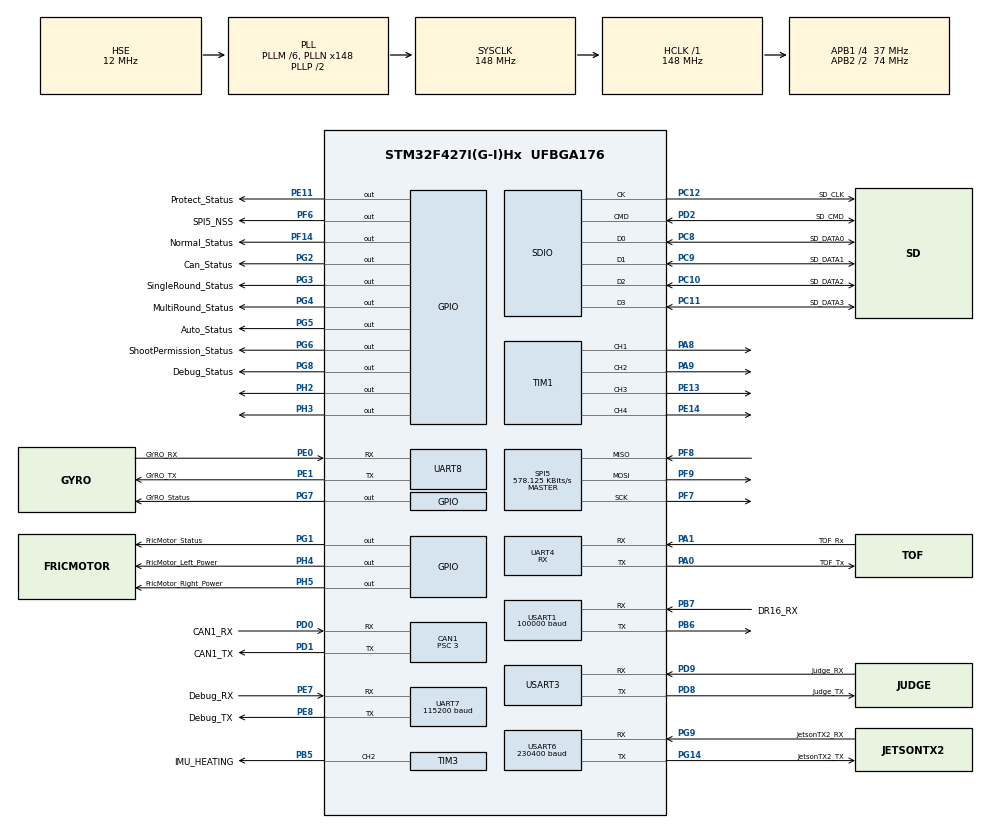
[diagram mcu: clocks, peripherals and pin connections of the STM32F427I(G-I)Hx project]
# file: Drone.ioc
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CAN1.ABOM=ENABLE
CAN1.AWUM=ENABLE
CAN1.BS1=CAN_BS1_9TQ
CAN1.BS2=CAN_BS2_4TQ
CAN1.CalculateTimeQuantum=81.08108108108108
CAN1.NART=DISABLE
CAN1.Prescaler=3
CAN1.TTCM=DISABLE
Dma.Request0=USART1_RX
Dma.Request1=USART3_RX
Dma.Request2=UART8_RX
Dma.Request3=USART6_RX
Dma.Request4=USART3_TX
Dma.Request5=USART6_TX
Dma.Request6=UART7_RX
Dma.Request7=SDIO_RX
Dma.Request8=SDIO_TX
Dma.Request9=UART4_RX
Dma.SDIO_RX.7.Direction=DMA_PERIPH_TO_MEMORY
Dma.SDIO_RX.7.FIFOMode=DMA_FIFOMODE_ENABLE
Dma.SDIO_RX.7.FIFOThreshold=DMA_FIFO_THRESHOLD_FULL
Dma.SDIO_RX.7.Instance=DMA2_Stream6
Dma.SDIO_RX.7.MemBurst=DMA_MBURST_INC4
Dma.SDIO_RX.7.MemDataAlignment=DMA_MDATAALIGN_WORD
Dma.SDIO_RX.7.MemInc=DMA_MINC_ENABLE
Dma.SDIO_RX.7.Mode=DMA_PFCTRL
Dma.SDIO_RX.7.PeriphBurst=DMA_PBURST_INC4
Dma.SDIO_RX.7.PeriphDataAlignment=DMA_PDATAALIGN_WORD
Dma.SDIO_RX.7.PeriphInc=DMA_PINC_DISABLE
Dma.SDIO_RX.7.Priority=DMA_PRIORITY_LOW
Dma.SDIO_TX.8.Direction=DMA_MEMORY_TO_PERIPH
Dma.SDIO_TX.8.FIFOMode=DMA_FIFOMODE_ENABLE
Dma.SDIO_TX.8.FIFOThreshold=DMA_FIFO_THRESHOLD_FULL
Dma.SDIO_TX.8.Instance=DMA2_Stream3
Dma.SDIO_TX.8.MemBurst=DMA_MBURST_INC4
Dma.SDIO_TX.8.MemDataAlignment=DMA_MDATAALIGN_WORD
Dma.SDIO_TX.8.MemInc=DMA_MINC_ENABLE
Dma.SDIO_TX.8.Mode=DMA_PFCTRL
Dma.SDIO_TX.8.PeriphBurst=DMA_PBURST_INC4
Dma.SDIO_TX.8.PeriphDataAlignment=DMA_PDATAALIGN_WORD
Dma.SDIO_TX.8.PeriphInc=DMA_PINC_DISABLE
Dma.SDIO_TX.8.Priority=DMA_PRIORITY_LOW
Dma.UART4_RX.9.Direction=DMA_PERIPH_TO_MEMORY
Dma.UART4_RX.9.FIFOMode=DMA_FIFOMODE_DISABLE
Dma.UART4_RX.9.Instance=DMA1_Stream2
Dma.UART4_RX.9.MemDataAlignment=DMA_MDATAALIGN_BYTE
Dma.UART4_RX.9.MemInc=DMA_MINC_ENABLE
Dma.UART4_RX.9.Mode=DMA_CIRCULAR
Dma.UART4_RX.9.PeriphDataAlignment=DMA_PDATAALIGN_BYTE
Dma.UART4_RX.9.PeriphInc=DMA_PINC_DISABLE
Dma.UART4_RX.9.Priority=DMA_PRIORITY_LOW
Dma.UART7_RX.6.Direction=DMA_PERIPH_TO_MEMORY
Dma.UART7_RX.6.FIFOMode=DMA_FIFOMODE_DISABLE
Dma.UART7_RX.6.Instance=DMA1_Stream3
Dma.UART7_RX.6.MemDataAlignment=DMA_MDATAALIGN_BYTE
Dma.UART7_RX.6.MemInc=DMA_MINC_ENABLE
Dma.UART7_RX.6.Mode=DMA_NORMAL
Dma.UART7_RX.6.PeriphDataAlignment=DMA_PDATAALIGN_BYTE
Dma.UART7_RX.6.PeriphInc=DMA_PINC_DISABLE
Dma.UART7_RX.6.Priority=DMA_PRIORITY_MEDIUM
Dma.UART8_RX.2.Direction=DMA_PERIPH_TO_MEMORY
Dma.UART8_RX.2.FIFOMode=DMA_FIFOMODE_DISABLE
Dma.UART8_RX.2.Instance=DMA1_Stream6
Dma.UART8_RX.2.MemDataAlignment=DMA_MDATAALIGN_BYTE
Dma.UART8_RX.2.MemInc=DMA_MINC_ENABLE
Dma.UART8_RX.2.Mode=DMA_NORMAL
Dma.UART8_RX.2.PeriphDataAlignment=DMA_PDATAALIGN_BYTE
Dma.UART8_RX.2.PeriphInc=DMA_PINC_DISABLE
Dma.UART8_RX.2.Priority=DMA_PRIORITY_VERY_HIGH
Dma.USART1_RX.0.Direction=DMA_PERIPH_TO_MEMORY
Dma.USART1_RX.0.FIFOMode=DMA_FIFOMODE_DISABLE
Dma.USART1_RX.0.Instance=DMA2_Stream2
Dma.USART1_RX.0.MemDataAlignment=DMA_MDATAALIGN_BYTE
Dma.USART1_RX.0.MemInc=DMA_MINC_ENABLE
Dma.USART1_RX.0.Mode=DMA_CIRCULAR
Dma.USART1_RX.0.PeriphDataAlignment=DMA_PDATAALIGN_BYTE
Dma.USART1_RX.0.PeriphInc=DMA_PINC_DISABLE
Dma.USART1_RX.0.Priority=DMA_PRIORITY_HIGH
Dma.USART3_RX.1.Direction=DMA_PERIPH_TO_MEMORY
Dma.USART3_RX.1.FIFOMode=DMA_FIFOMODE_DISABLE
Dma.USART3_RX.1.Instance=DMA1_Stream1
Dma.USART3_RX.1.MemDataAlignment=DMA_MDATAALIGN_BYTE
Dma.USART3_RX.1.MemInc=DMA_MINC_ENABLE
Dma.USART3_RX.1.Mode=DMA_NORMAL
Dma.USART3_RX.1.PeriphDataAlignment=DMA_PDATAALIGN_BYTE
Dma.USART3_RX.1.PeriphInc=DMA_PINC_DISABLE
Dma.USART3_RX.1.Priority=DMA_PRIORITY_MEDIUM
Dma.USART3_TX.4.Direction=DMA_MEMORY_TO_PERIPH
Dma.USART3_TX.4.FIFOMode=DMA_FIFOMODE_DISABLE
Dma.USART3_TX.4.Instance=DMA1_Stream4
Dma.USART3_TX.4.MemDataAlignment=DMA_MDATAALIGN_BYTE
Dma.USART3_TX.4.MemInc=DMA_MINC_ENABLE
Dma.USART3_TX.4.Mode=DMA_NORMAL
Dma.USART3_TX.4.PeriphDataAlignment=DMA_PDATAALIGN_BYTE
Dma.USART3_TX.4.PeriphInc=DMA_PINC_DISABLE
Dma.USART3_TX.4.Priority=DMA_PRIORITY_MEDIUM
Dma.USART6_RX.3.Direction=DMA_PERIPH_TO_MEMORY
Dma.USART6_RX.3.FIFOMode=DMA_FIFOMODE_DISABLE
Dma.USART6_RX.3.Instance=DMA2_Stream1
Dma.USART6_RX.3.MemDataAlignment=DMA_MDATAALIGN_BYTE
Dma.USART6_RX.3.MemInc=DMA_MINC_ENABLE
Dma.USART6_RX.3.Mode=DMA_NORMAL
Dma.USART6_RX.3.PeriphDataAlignment=DMA_PDATAALIGN_BYTE
Dma.USART6_RX.3.PeriphInc=DMA_PINC_DISABLE
Dma.USART6_RX.3.Priority=DMA_PRIORITY_MEDIUM
Dma.USART6_TX.5.Direction=DMA_MEMORY_TO_PERIPH
Dma.USART6_TX.5.FIFOMode=DMA_FIFOMODE_DISABLE
Dma.USART6_TX.5.Instance=DMA2_Stream7
Dma.USART6_TX.5.MemDataAlignment=DMA_MDATAALIGN_BYTE
Dma.USART6_TX.5.MemInc=DMA_MINC_ENABLE
Dma.USART6_TX.5.Mode=DMA_NORMAL
Dma.USART6_TX.5.PeriphDataAlignment=DMA_PDATAALIGN_BYTE
Dma.USART6_TX.5.PeriphInc=DMA_PINC_DISABLE
Dma.USART6_TX.5.Priority=DMA_PRIORITY_MEDIUM
FATFS._CODE_PAGE=936
FATFS._USE_LFN=2
FREERTOS.INCLUDE_eTaskGetState=1
FREERTOS.INCLUDE_uxTaskGetStackHighWaterMark=1
FREERTOS.INCLUDE_vTaskDelayUntil=1
FREERTOS.INCLUDE_xTaskGetCurrentTaskHandle=1
FREERTOS.INCLUDE_xTaskGetHandle=1
FREERTOS.MEMORY_ALLOCATION=2
FREERTOS.Tasks01=Task_Init,0,512,Task_Init_Config,As weak,NULL,Dynamic,NULL,NULL
FREERTOS.configGENERATE_RUN_TIME_STATS=1
FREERTOS.configIDLE_SHOULD_YIELD=0
FREERTOS.configMAX_TASK_NAME_LEN=32
FREERTOS.configMINIMAL_STACK_SIZE=512
FREERTOS.configTOTAL_HEAP_SIZE=20480
FREERTOS.configUSE_COUNTING_SEMAPHORES=1
FREERTOS.configUSE_STATS_FORMATTING_FUNCTIONS=1
FREERTOS.configUSE_TRACE_FACILITY=1
Mcu.Family=STM32F4
Mcu.Name=STM32F427I(G-I)Hx
Mcu.Package=UFBGA176
NVIC.CAN1_RX0_IRQn=true\:6\:0\:true\:false\:true\:true\:true\:true
NVIC.DMA1_Stream1_IRQn=true\:0\:0\:false\:false\:true\:true\:false\:true
NVIC.DMA1_Stream2_IRQn=true\:0\:0\:false\:false\:true\:true\:false\:true
NVIC.DMA1_Stream3_IRQn=true\:0\:0\:false\:false\:true\:true\:false\:true
NVIC.DMA1_Stream4_IRQn=true\:0\:0\:false\:false\:true\:true\:false\:true
NVIC.DMA1_Stream6_IRQn=true\:0\:0\:false\:false\:true\:true\:false\:true
NVIC.DMA2_Stream1_IRQn=true\:0\:0\:false\:false\:true\:true\:false\:true
NVIC.DMA2_Stream2_IRQn=true\:0\:0\:false\:false\:true\:true\:false\:true
NVIC.DMA2_Stream3_IRQn=true\:6\:0\:true\:false\:true\:true\:false\:true
NVIC.DMA2_Stream6_IRQn=true\:6\:0\:true\:false\:true\:true\:false\:true
NVIC.DMA2_Stream7_IRQn=true\:5\:0\:false\:false\:true\:false\:false\:true
NVIC.PriorityGroup=NVIC_PRIORITYGROUP_4
NVIC.SDIO_IRQn=true\:5\:0\:true\:false\:true\:true\:true\:true
NVIC.TIM2_IRQn=true\:0\:0\:false\:false\:true\:false\:false\:true
NVIC.TIM5_IRQn=true\:0\:0\:false\:false\:true\:true\:true\:true
NVIC.TimeBase=TIM2_IRQn
NVIC.TimeBaseIP=TIM2
NVIC.UART4_IRQn=true\:0\:0\:false\:false\:true\:true\:true\:true
NVIC.UART7_IRQn=true\:6\:0\:true\:false\:true\:true\:true\:true
NVIC.UART8_IRQn=true\:6\:0\:true\:false\:true\:true\:true\:true
NVIC.USART1_IRQn=true\:6\:0\:true\:false\:true\:true\:true\:true
NVIC.USART3_IRQn=true\:6\:0\:true\:false\:true\:true\:true\:true
NVIC.USART6_IRQn=true\:0\:0\:false\:true\:true\:1\:true\:true\:true
PA0/WKUP.GPIO_Label=TOF_Tx
PA0/WKUP.Mode=Asynchronous
PA0/WKUP.Signal=UART4_TX
PA1.GPIO_Label=TOF_Rx
PA1.Mode=Asynchronous
PA1.Signal=UART4_RX
PA13.GPIO_Label=SWDIO
PA13.Mode=Serial_Wire
PA13.Signal=SYS_JTMS-SWDIO
PA14.GPIO_Label=SWDCLK
PA14.Mode=Serial_Wire
PA14.Signal=SYS_JTCK-SWCLK
PA8.Signal=S_TIM1_CH1
PA9.Signal=S_TIM1_CH2
PB5.GPIO_Label=IMU_HEATING
PB5.Signal=S_TIM3_CH2
PB6.Mode=Asynchronous
PB6.Signal=USART1_TX
PB7.GPIO_Label=DR16_RX
PB7.Mode=Asynchronous
PB7.Signal=USART1_RX
PC10.GPIO_Label=SD_DATA2
PC10.Mode=SD_4_bits_Wide_bus
PC10.Signal=SDIO_D2
PC11.GPIO_Label=SD_DATA3
PC11.Mode=SD_4_bits_Wide_bus
PC11.Signal=SDIO_D3
PC12.GPIO_Label=SD_CLK
PC12.Mode=SD_4_bits_Wide_bus
PC12.Signal=SDIO_CK
PC8.GPIO_Label=SD_DATA0
PC8.Mode=SD_4_bits_Wide_bus
PC8.Signal=SDIO_D0
PC9.GPIO_Label=SD_DATA1
PC9.Mode=SD_4_bits_Wide_bus
PC9.Signal=SDIO_D1
PD0.GPIO_Label=CAN1_RX
PD0.Mode=Master
PD0.Signal=CAN1_RX
PD1.GPIO_Label=CAN1_TX
PD1.Mode=Master
PD1.Signal=CAN1_TX
PD2.GPIO_Label=SD_CMD
PD2.Mode=SD_4_bits_Wide_bus
PD2.Signal=SDIO_CMD
PD8.GPIO_Label=Judge_TX
PD8.Mode=Asynchronous
PD8.Signal=USART3_TX
PD9.GPIO_Label=Judge_RX
PD9.Mode=Asynchronous
PD9.Signal=USART3_RX
PE0.GPIO_Label=GYRO_RX
PE0.Mode=Asynchronous
PE0.Signal=UART8_RX
PE1.GPIO_Label=GYRO_TX
PE1.Mode=Asynchronous
PE1.Signal=UART8_TX
PE11.GPIO_Label=Protect_Status
PE11.PinState=GPIO_PIN_SET
PE11.Signal=GPIO_Output
PE13.Signal=S_TIM1_CH3
PE14.Signal=S_TIM1_CH4
PE7.GPIO_Label=Debug_RX
PE7.Mode=Asynchronous
PE7.Signal=UART7_RX
PE8.GPIO_Label=Debug_TX
PE8.Mode=Asynchronous
PE8.Signal=UART7_TX
PF14.GPIO_Label=Normal_Status
PF14.PinState=GPIO_PIN_SET
PF14.Signal=GPIO_Output
PF6.GPIO_Label=SPI5_NSS
PF6.GPIO_Speed=GPIO_SPEED_FREQ_VERY_HIGH
PF6.Signal=GPIO_Output
PF7.Mode=Full_Duplex_Master
PF7.Signal=SPI5_SCK
PF8.Mode=Full_Duplex_Master
PF8.Signal=SPI5_MISO
PF9.Mode=Full_Duplex_Master
PF9.Signal=SPI5_MOSI
PG1.GPIO_Label=FricMotor_Status
PG1.PinState=GPIO_PIN_SET
PG1.Signal=GPIO_Output
PG14.GPIO_Label=JetsonTX2_TX
PG14.GPIO_PuPd=GPIO_NOPULL
PG14.Mode=Asynchronous
PG14.Signal=USART6_TX
PG2.GPIO_Label=Can_Status
PG2.PinState=GPIO_PIN_SET
PG2.Signal=GPIO_Output
PG3.GPIO_Label=SingleRound_Status
PG3.PinState=GPIO_PIN_SET
PG3.Signal=GPIO_Output
PG4.GPIO_Label=MultiRound_Status
PG4.PinState=GPIO_PIN_SET
PG4.Signal=GPIO_Output
PG5.GPIO_Label=Auto_Status
PG5.PinState=GPIO_PIN_SET
PG5.Signal=GPIO_Output
PG6.GPIO_Label=ShootPermission_Status
PG6.PinState=GPIO_PIN_SET
PG6.Signal=GPIO_Output
PG7.GPIO_Label=GYRO_Status
PG7.PinState=GPIO_PIN_SET
PG7.Signal=GPIO_Output
PG8.GPIO_Label=Debug_Status
PG8.PinState=GPIO_PIN_SET
PG8.Signal=GPIO_Output
PG9.GPIO_Label=JetsonTX2_RX
PG9.GPIO_PuPd=GPIO_PULLUP
PG9.Mode=Asynchronous
PG9.Signal=USART6_RX
PH0/OSC_IN.Mode=HSE-External-Oscillator
PH0/OSC_IN.Signal=RCC_OSC_IN
PH1/OSC_OUT.Mode=HSE-External-Oscillator
PH1/OSC_OUT.Signal=RCC_OSC_OUT
PH2.Signal=GPIO_Output
PH3.Signal=GPIO_Output
PH4.GPIO_Label=FricMotor_Left_Power
PH4.Signal=GPIO_Output
PH5.GPIO_Label=FricMotor_Right_Power
PH5.Signal=GPIO_Output
ProjectManager.HeapSize=0x1000
ProjectManager.StackSize=0x1000
ProjectManager.TargetToolchain=MDK-ARM V5
RCC.48MHZClocksFreq_Value=19733333.333333332
RCC.AHBFreq_Value=148000000
RCC.APB1CLKDivider=RCC_HCLK_DIV4
RCC.APB1Freq_Value=37000000
RCC.APB1TimFreq_Value=74000000
RCC.APB2CLKDivider=RCC_HCLK_DIV2
RCC.APB2Freq_Value=74000000
RCC.APB2TimFreq_Value=148000000
RCC.CortexFreq_Value=148000000
RCC.HCLKFreq_Value=148000000
RCC.HSE_VALUE=12000000
RCC.HSI_VALUE=16000000
RCC.LSE_VALUE=32768
RCC.PLLM=6
RCC.PLLN=148
RCC.PLLQ=15
RCC.PLLSourceVirtual=RCC_PLLSOURCE_HSE
RCC.SYSCLKFreq_VALUE=148000000
RCC.SYSCLKSource=RCC_SYSCLKSOURCE_PLLCLK
RCC.VCOOutputFreq_Value=296000000
SDIO.ClockDiv=7
SH.S_TIM1_CH1.0=TIM1_CH1,PWM Generation1 CH1
SH.S_TIM1_CH2.0=TIM1_CH2,PWM Generation2 CH2
SH.S_TIM1_CH3.0=TIM1_CH3,PWM Generation3 CH3
SH.S_TIM1_CH4.0=TIM1_CH4,PWM Generation4 CH4
SH.S_TIM3_CH2.0=TIM3_CH2,PWM Generation2 CH2
SPI5.BaudRatePrescaler=SPI_BAUDRATEPRESCALER_128
SPI5.CalculateBaudRate=578.125 KBits/s
SPI5.Direction=SPI_DIRECTION_2LINES
SPI5.Mode=SPI_MODE_MASTER
SPI5.VirtualType=VM_MASTER
TIM1.Channel-PWM\ Generation1\ CH1=TIM_CHANNEL_1
TIM1.Channel-PWM\ Generation2\ CH2=TIM_CHANNEL_2
TIM1.Channel-PWM\ Generation3\ CH3=TIM_CHANNEL_3
TIM1.Channel-PWM\ Generation4\ CH4=TIM_CHANNEL_4
TIM3.Channel-PWM\ Generation2\ CH2=TIM_CHANNEL_2
TIM3.Period=2000-1
TIM3.Prescaler=81-1
TIM5.Period=200-1
TIM5.Prescaler=42000-1
UART4.Mode=MODE_RX
UART4.VirtualMode=Asynchronous
UART7.BaudRate=115200
UART7.VirtualMode=Asynchronous
UART8.VirtualMode=Asynchronous
USART1.BaudRate=100000
USART1.Mode=MODE_RX
USART1.Parity=PARITY_EVEN
USART1.VirtualMode=VM_ASYNC
USART3.VirtualMode=VM_ASYNC
USART6.BaudRate=230400
USART6.VirtualMode=VM_ASYNC
VP_FATFS_VS_SDIO.Mode=SDIO
VP_FREERTOS_VS_CMSIS_V1.Mode=CMSIS_V1
VP_SYS_VS_tim2.Mode=TIM2
VP_TIM5_VS_ClockSourceINT.Mode=Internal
board=custom

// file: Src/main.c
/* USER CODE BEGIN Header */
/**
  ******************************************************************************
  * @file           : main.c
  * @brief          : Main program body
  ******************************************************************************
  * @attention
  *
  * <h2><center>&copy; Copyright (c) 2019 STMicroelectronics.
  * All rights reserved.</center></h2>
  *
  * This software component is licensed by ST under BSD 3-Clause license,
  * the "License"; You may not use this file except in compliance with the
  * License. You may obtain a copy of the License at:
  *                        opensource.org/licenses/BSD-3-Clause
  *
  ******************************************************************************
  */
/* USER CODE END Header */

#include "main.h"
#include "cmsis_os.h"
#include "can.h"
#include "dma.h"
#include "fatfs.h"
#include "sdio.h"
#include "spi.h"
#include "tim.h"
#include "usart.h"
#include "gpio.h"

void SystemClock_Config(void);
void MX_FREERTOS_Init(void);
static void MX_NVIC_Init(void);

/* USER CODE BEGIN 0 */
extern void Update_SDtime(void);
/* USER CODE END 0 */

int main(void)
{

  /* MCU Configuration--------------------------------------------------------*/

  /* Reset of all peripherals, Initializes the Flash interface and the Systick. */
  HAL_Init();

  /* Configure the system clock */
  SystemClock_Config();

  /* Initialize all configured peripherals */
  MX_GPIO_Init();
  MX_DMA_Init();
  MX_CAN1_Init();
  MX_USART1_UART_Init();
  MX_TIM1_Init();
  MX_UART7_Init();
  MX_UART8_Init();
  MX_USART3_UART_Init();
  MX_USART6_UART_Init();
  MX_SPI5_Init();
  MX_TIM3_Init();
  MX_SDIO_SD_Init();
  MX_FATFS_Init();
  MX_UART4_Init();
  MX_TIM5_Init();

  /* Initialize interrupts */
  MX_NVIC_Init();
  /* USER CODE BEGIN 2 */
	HAL_TIM_Base_Start_IT(&htim5);
  /* USER CODE END 2 */

  /* Call init function for freertos objects (in freertos.c) */
  MX_FREERTOS_Init();
  /* Start scheduler */
  osKernelStart();

  /* We should never get here as control is now taken by the scheduler */
  /* Infinite loop */
  while (1)
  {

  }
}

void SystemClock_Config(void)
{
  RCC_OscInitTypeDef RCC_OscInitStruct = {0};
  RCC_ClkInitTypeDef RCC_ClkInitStruct = {0};

  /** Configure the main internal regulator output voltage
  */
  __HAL_RCC_PWR_CLK_ENABLE();
  __HAL_PWR_VOLTAGESCALING_CONFIG(PWR_REGULATOR_VOLTAGE_SCALE1);
  /** Initializes the CPU, AHB and APB busses clocks
  */
  RCC_OscInitStruct.OscillatorType = RCC_OSCILLATORTYPE_HSE;
  RCC_OscInitStruct.HSEState = RCC_HSE_ON;
  RCC_OscInitStruct.PLL.PLLState = RCC_PLL_ON;
  RCC_OscInitStruct.PLL.PLLSource = RCC_PLLSOURCE_HSE;
  RCC_OscInitStruct.PLL.PLLM = 6;
  RCC_OscInitStruct.PLL.PLLN = 148;
  RCC_OscInitStruct.PLL.PLLP = RCC_PLLP_DIV2;
  RCC_OscInitStruct.PLL.PLLQ = 15;
  if (HAL_RCC_OscConfig(&RCC_OscInitStruct) != HAL_OK)
  {
    Error_Handler();
  }
  /** Initializes the CPU, AHB and APB busses clocks
  */
  RCC_ClkInitStruct.ClockType = RCC_CLOCKTYPE_HCLK|RCC_CLOCKTYPE_SYSCLK
                              |RCC_CLOCKTYPE_PCLK1|RCC_CLOCKTYPE_PCLK2;
  RCC_ClkInitStruct.SYSCLKSource = RCC_SYSCLKSOURCE_PLLCLK;
  RCC_ClkInitStruct.AHBCLKDivider = RCC_SYSCLK_DIV1;
  RCC_ClkInitStruct.APB1CLKDivider = RCC_HCLK_DIV4;
  RCC_ClkInitStruct.APB2CLKDivider = RCC_HCLK_DIV2;

  if (HAL_RCC_ClockConfig(&RCC_ClkInitStruct, FLASH_LATENCY_4) != HAL_OK)
  {
    Error_Handler();
  }
}

/**
  * @brief NVIC Configuration.
  * @retval None
  */
static void MX_NVIC_Init(void)
{
  /* USART6_IRQn interrupt configuration */
  HAL_NVIC_SetPriority(USART6_IRQn, 5, 0);
  HAL_NVIC_EnableIRQ(USART6_IRQn);
}

 /**
  * @brief  Period elapsed callback in non blocking mode
  * @note   This function is called  when TIM2 interrupt took place, inside
  * HAL_TIM_IRQHandler(). It makes a direct call to HAL_IncTick() to increment
  * a global variable "uwTick" used as application time base.
  * @param  htim : TIM handle
  * @retval None
  */
void HAL_TIM_PeriodElapsedCallback(TIM_HandleTypeDef *htim)
{
  if (htim->Instance == TIM2) {
    HAL_IncTick();
  }
  /* USER CODE BEGIN Callback 1 */
	if (htim->Instance == htim5.Instance)
	{
		Update_SDtime();
	}
  /* USER CODE END Callback 1 */
}

void Error_Handler(void)
{
}

/************************ (C) COPYRIGHT STMicroelectronics *****END OF FILE****/

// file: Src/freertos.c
/* USER CODE BEGIN Header */
/**
  ******************************************************************************
  * File Name          : freertos.c
  * Description        : Code for freertos applications
  ******************************************************************************
  * @attention
  *
  * <h2><center>&copy; Copyright (c) 2019 STMicroelectronics.
  * All rights reserved.</center></h2>
  *
  * This software component is licensed by ST under Ultimate Liberty license
  * SLA0044, the "License"; You may not use this file except in compliance with
  * the License. You may obtain a copy of the License at:
  *                             www.st.com/SLA0044
  *
  ******************************************************************************
  */
/* USER CODE END Header */

#include "FreeRTOS.h"
#include "task.h"
#include "main.h"
#include "cmsis_os.h"

osThreadId Task_InitHandle;

void Task_Init_Config(void const * argument);

void MX_FREERTOS_Init(void); /* (MISRA C 2004 rule 8.1) */

/* GetIdleTaskMemory prototype (linked to static allocation support) */
void vApplicationGetIdleTaskMemory( StaticTask_t **ppxIdleTaskTCBBuffer, StackType_t **ppxIdleTaskStackBuffer, uint32_t *pulIdleTaskStackSize );

/* Hook prototypes */
void configureTimerForRunTimeStats(void);
unsigned long getRunTimeCounterValue(void);

/* USER CODE BEGIN 1 */
/* Functions needed when configGENERATE_RUN_TIME_STATS is on */
__weak void configureTimerForRunTimeStats(void)
{

}

__weak unsigned long getRunTimeCounterValue(void)
{
return 0;
}
/* USER CODE END 1 */

/* USER CODE BEGIN GET_IDLE_TASK_MEMORY */
static StaticTask_t xIdleTaskTCBBuffer;
static StackType_t xIdleStack[configMINIMAL_STACK_SIZE];

void vApplicationGetIdleTaskMemory( StaticTask_t **ppxIdleTaskTCBBuffer, StackType_t **ppxIdleTaskStackBuffer, uint32_t *pulIdleTaskStackSize )
{
  *ppxIdleTaskTCBBuffer = &xIdleTaskTCBBuffer;
  *ppxIdleTaskStackBuffer = &xIdleStack[0];
  *pulIdleTaskStackSize = configMINIMAL_STACK_SIZE;
  /* place for user code */
}
/* USER CODE END GET_IDLE_TASK_MEMORY */

void MX_FREERTOS_Init(void) {

  /* Create the thread(s) */
  /* definition and creation of Task_Init */
  osThreadDef(Task_Init, Task_Init_Config, osPriorityNormal, 0, 512);
  Task_InitHandle = osThreadCreate(osThread(Task_Init), NULL);

}

__weak void Task_Init_Config(void const * argument)
{
}

/************************ (C) COPYRIGHT STMicroelectronics *****END OF FILE****/
